VERSION ""

NS_ :

BS_:

BU_:

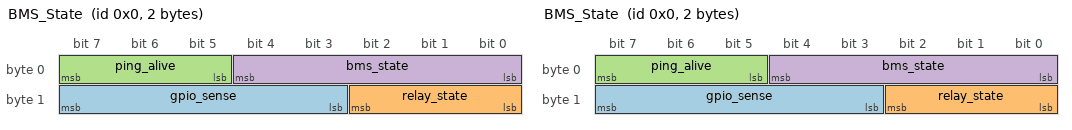
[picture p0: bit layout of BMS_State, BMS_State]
BO_ 0 BMS_State: 2 Vector__XXX
 SG_ gpio_sense : 11|5@1+ (1,0) [0|0] "" Vector__XXX
 SG_ relay_state : 8|3@1+ (1,0) [0|0] "" Vector__XXX
 SG_ ping_alive : 5|3@1+ (1,0) [0|0] "" Vector__XXX
 SG_ bms_state : 0|5@1+ (1,0) [0|0] "" Vector__XXX
BO_ 0 BMS_State: 2 Vector__XXX
 SG_ gpio_sense : 11|5@1+ (1,0) [0|0] "" Vector__XXX
 SG_ relay_state : 8|3@1+ (1,0) [0|0] "" Vector__XXX
 SG_ ping_alive : 5|3@1+ (1,0) [0|0] "" Vector__XXX
 SG_ bms_state : 0|5@1+ (1,0) [0|0] "" Vector__XXX

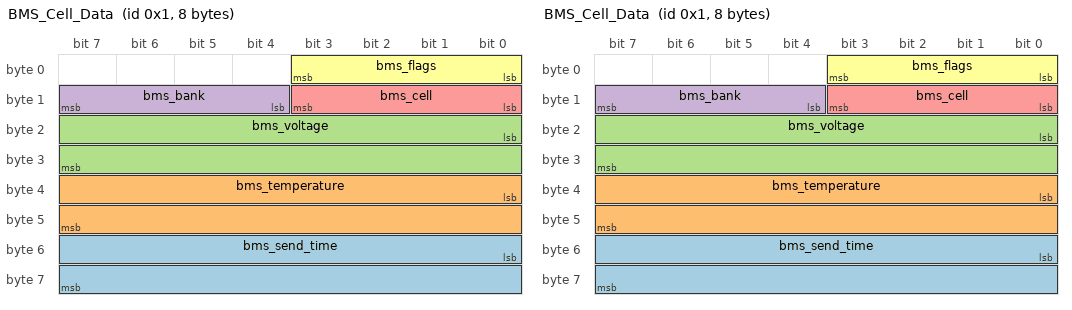
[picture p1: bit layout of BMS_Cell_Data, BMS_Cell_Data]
BO_ 1 BMS_Cell_Data: 8 Vector__XXX
 SG_ bms_send_time : 48|16@1+ (1,0) [0|0] "" Vector__XXX
 SG_ bms_temperature : 32|16@1+ (1,0) [0|0] "" Vector__XXX
 SG_ bms_voltage : 16|16@1+ (1,0) [0|0] "" Vector__XXX
 SG_ bms_bank : 12|4@1+ (1,0) [0|0] "" Vector__XXX
 SG_ bms_cell : 8|4@1+ (1,0) [0|0] "" Vector__XXX
 SG_ bms_flags : 0|4@1+ (1,0) [0|0] "" Vector__XXX
BO_ 1 BMS_Cell_Data: 8 Vector__XXX
 SG_ bms_send_time : 48|16@1+ (1,0) [0|0] "" Vector__XXX
 SG_ bms_temperature : 32|16@1+ (1,0) [0|0] "" Vector__XXX
 SG_ bms_voltage : 16|16@1+ (1,0) [0|0] "" Vector__XXX
 SG_ bms_bank : 12|4@1+ (1,0) [0|0] "" Vector__XXX
 SG_ bms_cell : 8|4@1+ (1,0) [0|0] "" Vector__XXX
 SG_ bms_flags : 0|4@1+ (1,0) [0|0] "" Vector__XXX

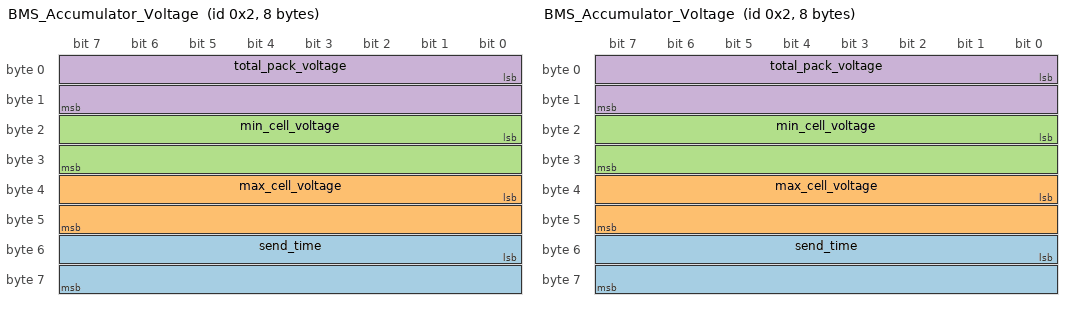
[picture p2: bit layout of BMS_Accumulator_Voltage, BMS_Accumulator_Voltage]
BO_ 2 BMS_Accumulator_Voltage: 8 Vector__XXX
 SG_ send_time : 48|16@1+ (1,0) [0|0] "" Vector__XXX
 SG_ max_cell_voltage : 32|16@1+ (1,0) [0|0] "" Vector__XXX
 SG_ min_cell_voltage : 16|16@1+ (1,0) [0|0] "" Vector__XXX
 SG_ total_pack_voltage : 0|16@1+ (1,0) [0|0] "" Vector__XXX
BO_ 2 BMS_Accumulator_Voltage: 8 Vector__XXX
 SG_ send_time : 48|16@1+ (1,0) [0|0] "" Vector__XXX
 SG_ max_cell_voltage : 32|16@1+ (1,0) [0|0] "" Vector__XXX
 SG_ min_cell_voltage : 16|16@1+ (1,0) [0|0] "" Vector__XXX
 SG_ total_pack_voltage : 0|16@1+ (1,0) [0|0] "" Vector__XXX

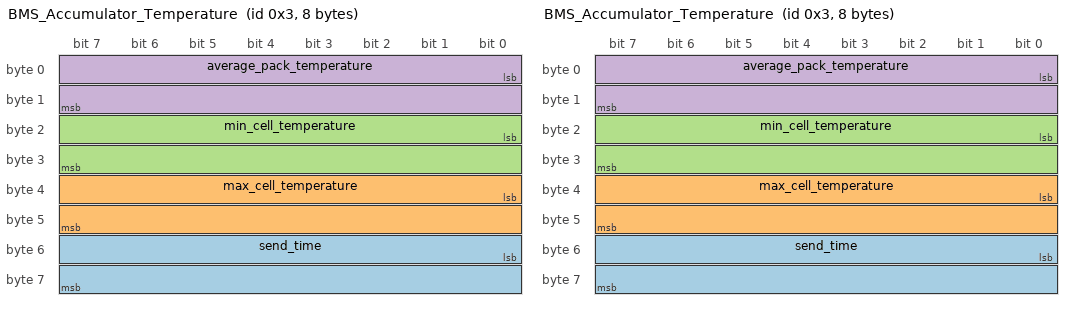
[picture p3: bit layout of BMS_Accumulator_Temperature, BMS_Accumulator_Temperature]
BO_ 3 BMS_Accumulator_Temperature: 8 Vector__XXX
 SG_ send_time : 48|16@1+ (1,0) [0|0] "" Vector__XXX
 SG_ max_cell_temperature : 32|16@1+ (1,0) [0|0] "" Vector__XXX
 SG_ min_cell_temperature : 16|16@1+ (1,0) [0|0] "" Vector__XXX
 SG_ average_pack_temperature : 0|16@1+ (1,0) [0|0] "" Vector__XXX

BO_ 4 normalized_brake: 1 Vector__XXX
 SG_ normalized_brake : 0|8@1+ (1,0) [0|0] "" Vector__XXX
BO_ 3 BMS_Accumulator_Temperature: 8 Vector__XXX
 SG_ send_time : 48|16@1+ (1,0) [0|0] "" Vector__XXX
 SG_ max_cell_temperature : 32|16@1+ (1,0) [0|0] "" Vector__XXX
 SG_ min_cell_temperature : 16|16@1+ (1,0) [0|0] "" Vector__XXX
 SG_ average_pack_temperature : 0|16@1+ (1,0) [0|0] "" Vector__XXX

BO_ 4 normalized_brake: 1 Vector__XXX
 SG_ normalized_brake : 0|8@1+ (1,0) [0|0] "" Vector__XXX

BO_ 5 BSPD_State: 1 Vector__XXX
BO_ 5 BSPD_State: 1 Vector__XXX
 SG_ bspd_state : 0|8@1+ (1,0) [0|0] "" Vector__XXX

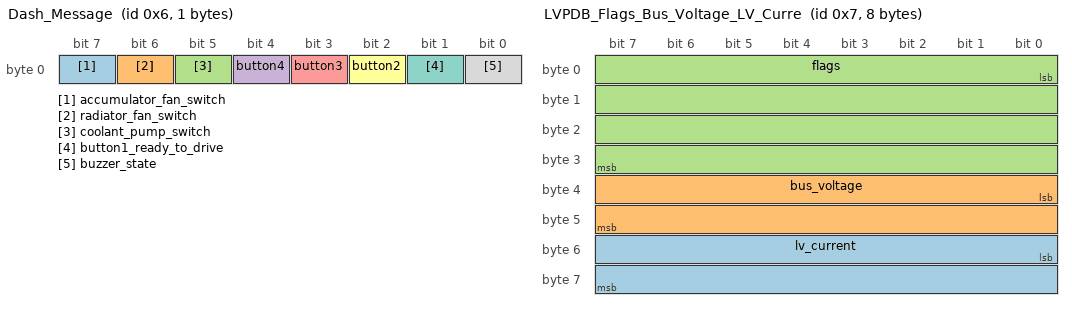
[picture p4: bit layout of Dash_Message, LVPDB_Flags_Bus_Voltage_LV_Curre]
BO_ 6 Dash_Message: 1 Vector__XXX
BO_ 6 Dash_Message: 1 Vector__XXX
 SG_ accumulator_fan_switch : 7|1@1+ (1,0) [0|0] "" Vector__XXX
 SG_ radiator_fan_switch : 6|1@1+ (1,0) [0|0] "" Vector__XXX
 SG_ coolant_pump_switch : 5|1@1+ (1,0) [0|0] "" Vector__XXX
 SG_ button4 : 4|1@1+ (1,0) [0|0] "" Vector__XXX
 SG_ button3 : 3|1@1+ (1,0) [0|0] "" Vector__XXX
 SG_ button2 : 2|1@1+ (1,0) [0|0] "" Vector__XXX
 SG_ button1_ready_to_drive : 1|1@1+ (1,0) [0|0] "" Vector__XXX
 SG_ buzzer_state : 0|1@1+ (1,0) [0|0] "" Vector__XXX

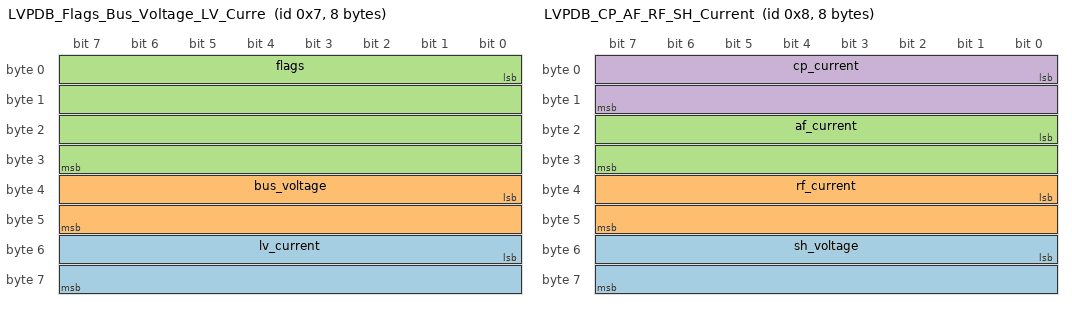
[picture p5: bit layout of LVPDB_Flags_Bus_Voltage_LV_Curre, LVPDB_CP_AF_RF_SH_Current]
BO_ 7 LVPDB_Flags_Bus_Voltage_LV_Curre: 8 Vector__XXX
 SG_ lv_current : 48|16@1+ (1,0) [0|0] "" Vector__XXX
 SG_ bus_voltage : 32|16@1+ (1,0) [0|0] "" Vector__XXX
 SG_ flags : 0|32@1+ (1,0) [0|0] "" Vector__XXX
BO_ 7 LVPDB_Flags_Bus_Voltage_LV_Curre: 8 Vector__XXX
 SG_ lv_current : 48|16@1+ (1,0) [0|0] "" Vector__XXX
 SG_ bus_voltage : 32|16@1+ (1,0) [0|0] "" Vector__XXX
 SG_ flags : 0|32@1+ (1,0) [0|0] "" Vector__XXX

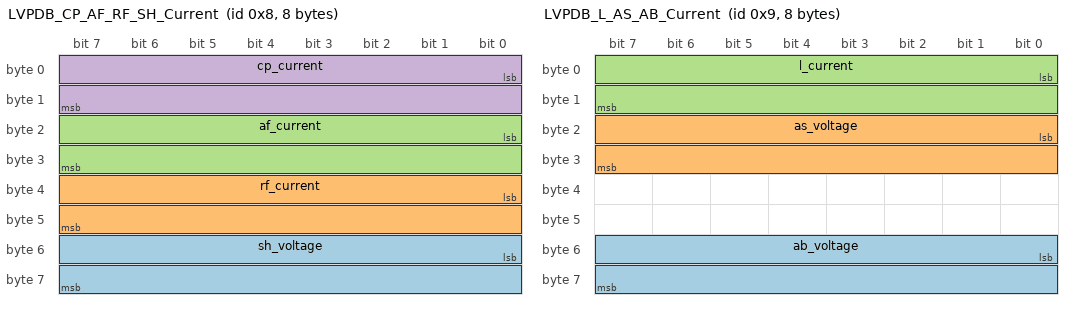
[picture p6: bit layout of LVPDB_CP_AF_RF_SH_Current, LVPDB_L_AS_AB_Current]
BO_ 8 LVPDB_CP_AF_RF_SH_Current: 8 Vector__XXX
 SG_ sh_voltage : 48|16@1+ (1,0) [0|0] "" Vector__XXX
 SG_ rf_current : 32|16@1+ (1,0) [0|0] "" Vector__XXX
 SG_ af_current : 16|16@1+ (1,0) [0|0] "" Vector__XXX
 SG_ cp_current : 0|16@1+ (1,0) [0|0] "" Vector__XXX
BO_ 8 LVPDB_CP_AF_RF_SH_Current: 8 Vector__XXX
 SG_ sh_voltage : 48|16@1+ (1,0) [0|0] "" Vector__XXX
 SG_ rf_current : 32|16@1+ (1,0) [0|0] "" Vector__XXX
 SG_ af_current : 16|16@1+ (1,0) [0|0] "" Vector__XXX
 SG_ cp_current : 0|16@1+ (1,0) [0|0] "" Vector__XXX

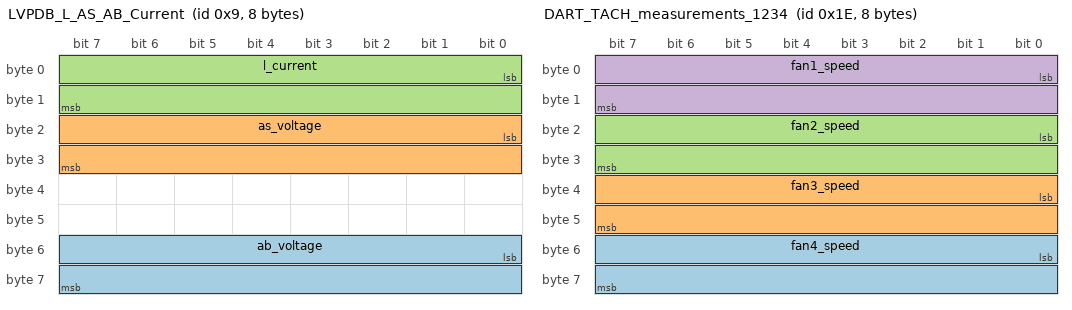
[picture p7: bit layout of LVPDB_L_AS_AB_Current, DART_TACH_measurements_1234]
BO_ 9 LVPDB_L_AS_AB_Current: 8 Vector__XXX
 SG_ ab_voltage : 48|16@1+ (1,0) [0|0] "" Vector__XXX
 SG_ as_voltage : 16|16@1+ (1,0) [0|0] "" Vector__XXX
 SG_ l_current : 0|16@1+ (1,0) [0|0] "" Vector__XXX
BO_ 9 LVPDB_L_AS_AB_Current: 8 Vector__XXX
 SG_ ab_voltage : 48|16@1+ (1,0) [0|0] "" Vector__XXX
 SG_ as_voltage : 16|16@1+ (1,0) [0|0] "" Vector__XXX
 SG_ l_current : 0|16@1+ (1,0) [0|0] "" Vector__XXX

BO_ 30 DART_TACH_measurements_1234: 8 Vector__XXX
BO_ 30 DART_TACH_measurements_1234: 8 Vector__XXX
 SG_ fan4_speed : 48|16@1+ (1,0) [0|0] "" Vector__XXX
 SG_ fan3_speed : 32|16@1+ (1,0) [0|0] "" Vector__XXX
 SG_ fan2_speed : 16|16@1+ (1,0) [0|0] "" Vector__XXX
 SG_ fan1_speed : 0|16@1+ (1,0) [0|0] "" Vector__XXX

BO_ 31 DART_TACH_measurements_5: 2 Vector__XXX
BO_ 31 DART_TACH_measurements_5: 2 Vector__XXX
 SG_ fan5_speed : 0|16@1+ (1,0) [0|0] "" Vector__XXX

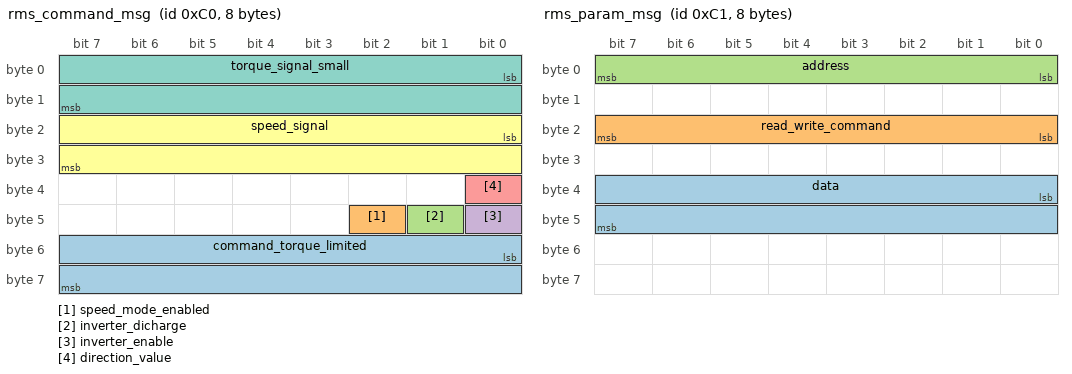
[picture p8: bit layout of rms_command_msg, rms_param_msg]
BO_ 192 rms_command_msg: 8 Vector__XXX
 SG_ command_torque_limited : 48|16@1+ (1,0) [0|0] "" Vector__XXX
 SG_ speed_mode_enabled : 42|1@1+ (1,0) [0|0] "" Vector__XXX
 SG_ inverter_dicharge : 41|1@1+ (1,0) [0|0] "" Vector__XXX
 SG_ inverter_enable : 40|1@1+ (1,0) [0|0] "" Vector__XXX
 SG_ direction_value : 32|1@1+ (1,0) [0|0] "" Vector__XXX
 SG_ speed_signal : 16|16@1+ (1,0) [0|0] "" Vector__XXX
 SG_ torque_signal_small : 0|16@1+ (1,0) [0|0] "" Vector__XXX

BO_ 193 rms_param_msg: 8 Vector__XXX
 SG_ data : 32|16@1+ (1,0) [0|0] "" Vector__XXX
 SG_ read_write_command : 16|8@1+ (1,0) [0|0] "" Vector__XXX
 SG_ address : 0|8@1+ (1,0) [0|0] "" Vector__XXX

BO_ 224 FEB_PING_PONG_counter1: 8 Vector__XXX
 SG_ counter : 0|32@1- (1,0) [0|0] "" Vector__XXX

BO_ 225 FEB_PING_PONG_counter2: 8 Vector__XXX
 SG_ counter : 0|32@1- (1,0) [0|0] "" Vector__XXX

BO_ 226 FEB_PING_PONG_counter3: 8 Vector__XXX
 SG_ counter : 0|32@1- (1,0) [0|0] "" Vector__XXX

BO_ 227 FEB_PING_PONG_counter4: 8 Vector__XXX
 SG_ counter : 0|32@1- (1,0) [0|0] "" Vector__XXX

CM_ BO_ 0 "BMS message for BMS state.";
CM_ BO_ 1 "BMS message for cell data.";
CM_ BO_ 2 "BMS message for accumulator voltage.";
CM_ BO_ 3 "BMS message for accumulator temperature.";
CM_ BO_ 4 "PCU normalized brake message";
CM_ BO_ 5 "BSPD message.";
CM_ BO_ 6 "Dash message";
CM_ BO_ 7 "LVPDB message for flags, bus voltage, LV current.";
CM_ BO_ 8 "LVPDB message for Coolant Pump Current, Accumulator Fans, Radiator Fans, Shutdown Source.";
CM_ BO_ 9 "LVPDB message for .";
CM_ BO_ 30 "DART message for Tachometer measurements first 4 fan speeds.";
CM_ BO_ 31 "DART message for Tachometer measurements 5th fan speed.";
CM_ BO_ 192 "RMS command message.";
CM_ BO_ 193 "param_message.";
CM_ BO_ 224 "PING PONG counter1.";
CM_ BO_ 225 "PING PONG counter2.";
CM_ BO_ 226 "PING PONG counter3.";
CM_ BO_ 227 "PING PONG counter4.";
BA_DEF_ BO_  "SystemMessageLongSymbol" STRING ;
BA_DEF_DEF_  "SystemMessageLongSymbol" "";
BA_ "SystemMessageLongSymbol" BO_ 7 "LVPDB_Flags_Bus_Voltage_LV_Current";
BA_ "SystemMessageLongSymbol" BO_ 7 "LVPDB_Flags_Bus_Voltage_LV_Current";
